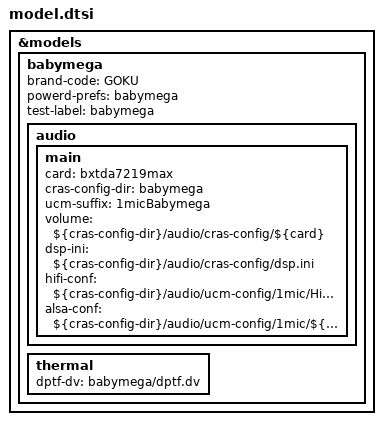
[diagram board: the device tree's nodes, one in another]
/*
 * Copyright 2018 The Chromium OS Authors. All rights reserved.
 *
 * Use of this source code is governed by a BSD-style license that can be
 * found in the LICENSE file.
 */

&models {
	babymega: babymega {
		brand-code = "GOKU";
		powerd-prefs = "babymega";
		test-label = "babymega";
		audio {
			main {
				card = "bxtda7219max";
				cras-config-dir = "babymega";
				ucm-suffix = "1micBabymega";
				volume = "${cras-config-dir}/audio/cras-config/${card}";
				dsp-ini = "${cras-config-dir}/audio/cras-config/dsp.ini";
				hifi-conf = "${cras-config-dir}/audio/ucm-config/1mic/HiFi";
				alsa-conf = "${cras-config-dir}/audio/ucm-config/1mic/${card}.conf";
			};
		};
		thermal {
			dptf-dv = "babymega/dptf.dv";
		};
	};
};
